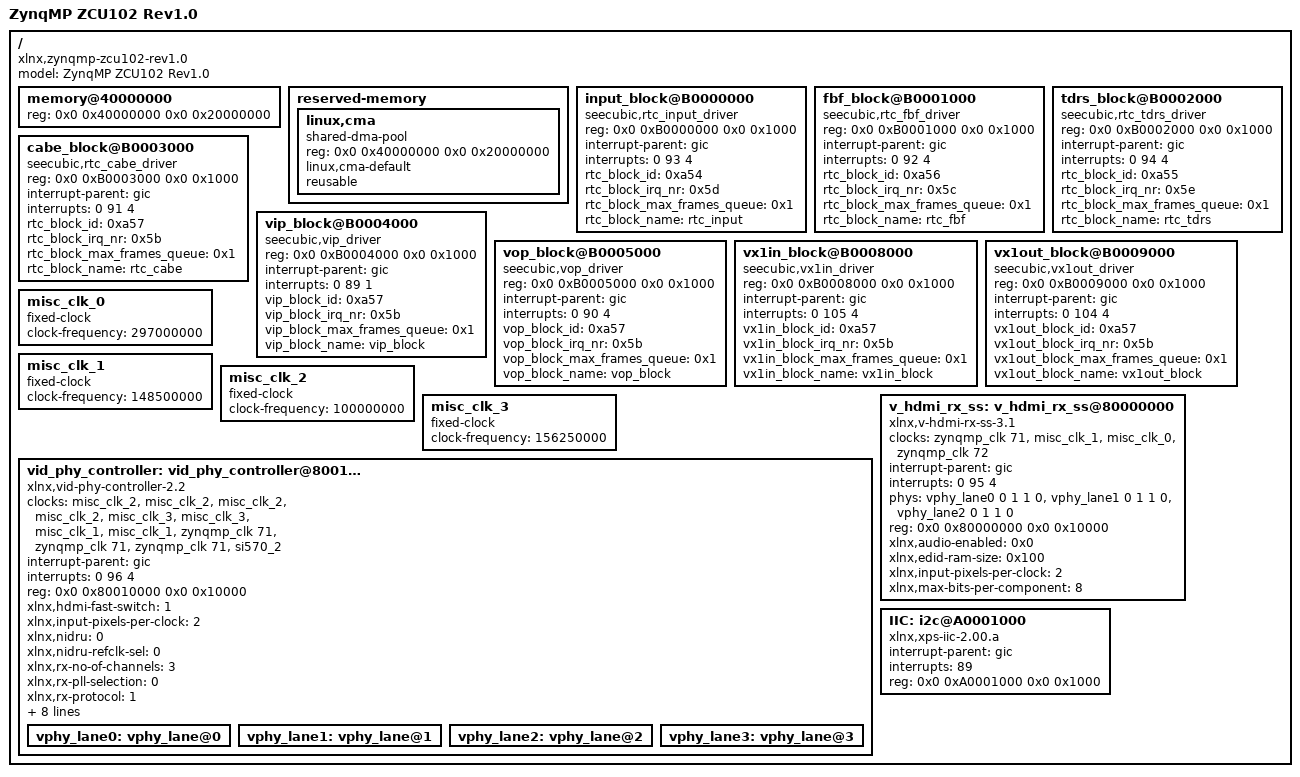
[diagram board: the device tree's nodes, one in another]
#include "zynqmp-zcu102-rev1.0.dts"

/ {
    model = "ZynqMP ZCU102 Rev1.0";
    compatible = "xlnx,zynqmp-zcu102-rev1.0", "xlnx,zynqmp-zcu102", "xlnx,zynqmp";

    memory@40000000 {
	device_type = "memory";
	reg = <0x0 0x40000000 0x0 0x20000000>;
    };

    reserved-memory {
    	#address-cells = <0x2>;
    	#size-cells = <0x2>;
    	ranges;
    
    	linux,cma {
    	    compatible = "shared-dma-pool";
    	    reg = <0x0 0x40000000 0x0 0x20000000>;
    	    linux,cma-default;
    	    reusable;
    	};
    };

    input_block@B0000000 {
    	#address-cells = <0x2>;
		#size-cells = <0x2>;
		compatible = "seecubic,rtc_input_driver";
		reg = <0x0 0xB0000000 0x0 0x1000>;
		interrupt-parent = <&gic>;
		interrupt-names = "input";
		interrupts = <0 93 4>;
		rtc_block_id = <0xa54>;
		rtc_block_irq_nr = <0x5d>;
		rtc_block_max_frames_queue = <0x1>;
		rtc_block_name = "rtc_input";
    };

    fbf_block@B0001000 {
		#address-cells = <0x2>;
		#size-cells = <0x2>;
		compatible = "seecubic,rtc_fbf_driver";
		reg = <0x0 0xB0001000 0x0 0x1000>;
		interrupt-parent = <&gic>;
		interrupt-names = "fbf";
		interrupts = <0 92 4>;
		rtc_block_id = <0xa56>;
		rtc_block_irq_nr = <0x5c>;
		rtc_block_max_frames_queue = <0x1>;
		rtc_block_name = "rtc_fbf";
    };

    tdrs_block@B0002000 {
		#address-cells = <0x2>;
		#size-cells = <0x2>;
		compatible = "seecubic,rtc_tdrs_driver";
		reg = <0x0 0xB0002000 0x0 0x1000>;
		interrupt-parent = <&gic>;
		interrupt-names = "tdrs";
		interrupts = <0 94  4>;
		rtc_block_id = <0xa55>;
		rtc_block_irq_nr = <0x5e>;
		rtc_block_max_frames_queue = <0x1>;
		rtc_block_name = "rtc_tdrs";
    };

    cabe_block@B0003000 {
		#address-cells = <0x2>;
		#size-cells = <0x2>;
		compatible = "seecubic,rtc_cabe_driver";
		reg = <0x0 0xB0003000 0x0 0x1000>;
		interrupt-parent = <&gic>;
		interrupt-names = "cabe";
		interrupts = <0 91 4>;
		rtc_block_id = <0xa57>;
		rtc_block_irq_nr = <0x5b>;
		rtc_block_max_frames_queue = <0x1>;
		rtc_block_name = "rtc_cabe";
    };

    vip_block@B0004000{
		#address-cells = <0x2>;
		#size-cells = <0x2>;
		compatible = "seecubic,vip_driver";
		reg = <0x0 0xB0004000 0x0 0x1000>;
		interrupt-parent = <&gic>;
		interrupt-names = "vip";
		interrupts = <0 89 1>;
		vip_block_id = <0xa57>;
		vip_block_irq_nr = <0x5b>;
		vip_block_max_frames_queue = <0x1>;
		vip_block_name = "vip_block";
    };

    vop_block@B0005000{
		#address-cells = <0x2>;
		#size-cells = <0x2>;
		compatible = "seecubic,vop_driver";
		reg = <0x0 0xB0005000 0x0 0x1000>;
		interrupt-parent = <&gic>;
		interrupt-names = "vop";
		interrupts = <0 90 4>;
		vop_block_id = <0xa57>;
		vop_block_irq_nr = <0x5b>;
		vop_block_max_frames_queue = <0x1>;
		vop_block_name = "vop_block";
    };


    vx1in_block@B0008000{
		#address-cells = <0x2>;
		#size-cells = <0x2>;
		compatible = "seecubic,vx1in_driver";
		reg = <0x0 0xB0008000 0x0 0x1000>;
		interrupt-parent = <&gic>;
		interrupt-names = "vx1in";
		interrupts = <0 105 4>;
		vx1in_block_id = <0xa57>;
		vx1in_block_irq_nr = <0x5b>;
		vx1in_block_max_frames_queue = <0x1>;
		vx1in_block_name = "vx1in_block";
    };

    vx1out_block@B0009000{
		#address-cells = <0x2>;
		#size-cells = <0x2>;
		compatible = "seecubic,vx1out_driver";
		reg = <0x0 0xB0009000 0x0 0x1000>;
		interrupt-parent = <&gic>;
		interrupt-names = "vx1out";
		interrupts = <0 104 4>;
		vx1out_block_id = <0xa57>;
		vx1out_block_irq_nr = <0x5b>;
		vx1out_block_max_frames_queue = <0x1>;
		vx1out_block_name = "vx1out_block";
    };


	misc_clk_0: misc_clk_0 {
		#clock-cells = <0>;
		clock-frequency = <297000000>;
		compatible = "fixed-clock";
	};

	misc_clk_1: misc_clk_1 {
		#clock-cells = <0>;
		clock-frequency = <148500000>;
		compatible = "fixed-clock";
	};

	misc_clk_2: misc_clk_2 {
		#clock-cells = <0>;
		clock-frequency = <100000000>;
		compatible = "fixed-clock";
	};
	misc_clk_3: misc_clk_3 {
		#clock-cells = <0>;
		clock-frequency = <156250000>;
		compatible = "fixed-clock";
	};

	/* Adding the device information for HDMI phy */
	vid_phy_controller: vid_phy_controller@80010000 {
		clock-names = "mgtrefclk0_pad_p_in", "mgtrefclk0_pad_n_in", "mgtrefclk1_pad_p_in", "mgtrefclk1_pad_n_in", "gtsouthrefclk0_in", "gtsouthrefclk0_odiv2_in", "vid_phy_tx_axi4s_aclk", "vid_phy_rx_axi4s_aclk", "vid_phy_sb_aclk", "vid_phy_axi4lite_aclk", "drpclk", "dru-clk";
		clocks = <&misc_clk_2>, <&misc_clk_2>, <&misc_clk_2>, <&misc_clk_2>, <&misc_clk_3>, <&misc_clk_3>, <&misc_clk_1>, <&misc_clk_1>, <&zynqmp_clk 71>, <&zynqmp_clk 71>, <&zynqmp_clk 71>, <&si570_2>;
		compatible = "xlnx,vid-phy-controller-2.2", "xlnx,vid-phy-controller-2.1";
		interrupt-names = "irq";
		interrupt-parent = <&gic>;
		interrupts = <0 96 4>;
		reg = <0x0 0x80010000 0x0 0x10000>;
		xlnx,hdmi-fast-switch = <1>;
		xlnx,input-pixels-per-clock = <2>;
		xlnx,nidru = <0>;
		xlnx,nidru-refclk-sel = <0>;
		xlnx,rx-no-of-channels = <3>;
		xlnx,rx-pll-selection = <0>;
		xlnx,rx-protocol = <1>;
		xlnx,rx-refclk-sel = <1>;
		xlnx,transceiver-type = <5>;
		xlnx,transceiver-width = <2>;
		xlnx,tx-buffer-bypass = <1>;
		xlnx,tx-no-of-channels = <3>;
		xlnx,tx-pll-selection = <6>;
		xlnx,tx-protocol = <1>;
		xlnx,tx-refclk-sel = <0>;
		vphy_lane0: vphy_lane@0 {
			#phy-cells = <4>;
		};
		vphy_lane1: vphy_lane@1 {
			#phy-cells = <4>;
		};
		vphy_lane2: vphy_lane@2 {
			#phy-cells = <4>;
		};
		vphy_lane3: vphy_lane@3 {
			#phy-cells = <4>;
		};
	};

	/* Adding the dts information for HDMI Rx driver */ 
	v_hdmi_rx_ss: v_hdmi_rx_ss@80000000 {
		// User needs to change the property xlnx,audio-enabled=<0x1> based on the HDMI audio path
//		clock-names = "s_axi_cpu_aclk", "link_clk", "s_axis_audio_aclk", "video_clk", "s_axis_video_aclk";
//		clocks = <&zynqmp_clk 71>, <&misc_clk_1>, <&audio_ss_0_clk_wiz 0>, <&misc_clk_0>, <&zynqmp_clk 72>;
		clock-names = "s_axi_cpu_aclk", "link_clk", "video_clk", "s_axis_video_aclk";
		clocks = <&zynqmp_clk 71>, <&misc_clk_1>, <&misc_clk_0>, <&zynqmp_clk 72>;
		compatible = "xlnx,v-hdmi-rx-ss-3.1", "xlnx,v-hdmi-rx-ss-3.0";
		interrupt-names = "hdmi_rx";
		interrupt-parent = <&gic>;
		interrupts = <0 95 4>;
		phy-names = "hdmi-phy0", "hdmi-phy1", "hdmi-phy2";
		phys = <&vphy_lane0 0 1 1 0>, <&vphy_lane1 0 1 1 0>, <&vphy_lane2 0 1 1 0>;
		reg = <0x0 0x80000000 0x0 0x10000>;
		xlnx,audio-enabled = <0x0>;
		xlnx,edid-ram-size = <0x100>;
		xlnx,input-pixels-per-clock = <2>;
		xlnx,max-bits-per-component = <8>;
	};
	IIC: i2c@A0001000 {
		compatible = "xlnx,xps-iic-2.00.a";
		interrupt-parent = <&gic>;
		interrupts = < 89 >;
		#address-cells = <1>;
		#size-cells = <0>;
		reg = <0x0 0xA0001000 0x0 0x1000>;

	} ;

};
